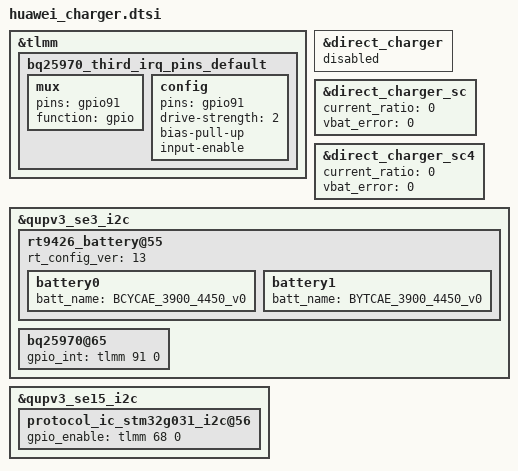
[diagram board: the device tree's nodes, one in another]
&tlmm {
	bq25970_third_irq_pins_default {
		mux {
			pins = "gpio91";
			function = "gpio";
		};
		config {
			pins = "gpio91";
			drive-strength = <2>;
			bias-pull-up;
			input-enable;
		};
	};
};

&direct_charger {
	status = "disabled";
};

&direct_charger_sc {
	current_ratio = "0";
	vbat_error = "0";
};

&direct_charger_sc4 {
	current_ratio = "0";
	vbat_error = "0";
};

&qupv3_se3_i2c {
	rt9426_battery@55{
		rt_config_ver = <13>;
		battery0{
			batt_name = "BCYCAE_3900_4450_v0";
			#include "../../../huawei_charger/rt9426_0P5mohm_BITCAE_3900mAh_4V45_BT216.dtsi"
		};
		battery1{
                        batt_name = "BYTCAE_3900_4450_v0";
                        #include "../../../huawei_charger/rt9426_0P5mohm_BITCAE_3900mAh_4V45_BT216.dtsi"
                };
	};
	bq25970@65 {
		gpio_int = <&tlmm 91 0>;
		status = "ok";
	};
};

&qupv3_se15_i2c {
	protocol_ic_stm32g031_i2c@56 {
		gpio_enable = <&tlmm 68 0>;
	};
};
